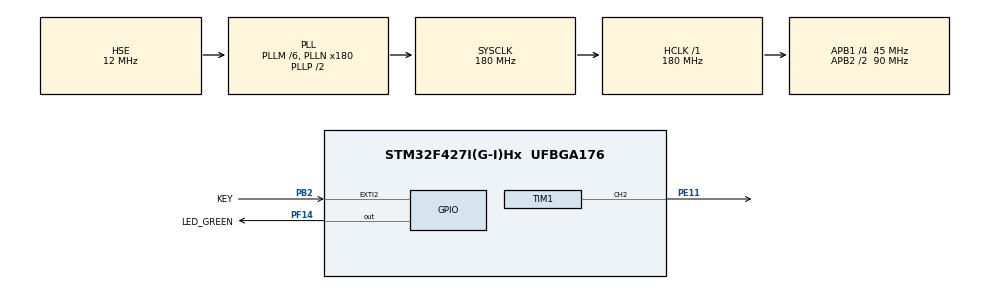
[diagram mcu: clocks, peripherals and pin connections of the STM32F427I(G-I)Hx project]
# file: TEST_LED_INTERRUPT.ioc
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Mcu.Family=STM32F4
Mcu.Name=STM32F427I(G-I)Hx
Mcu.Package=UFBGA176
NVIC.EXTI2_IRQn=true\:0\:0\:false\:false\:true\:true\:true\:true
NVIC.PriorityGroup=NVIC_PRIORITYGROUP_4
NVIC.TIM1_UP_TIM10_IRQn=true\:0\:0\:false\:false\:true\:true\:true\:true
NVIC.TIM6_DAC_IRQn=true\:0\:0\:false\:false\:true\:true\:true\:true
PA13.Mode=Serial_Wire
PA13.Signal=SYS_JTMS-SWDIO
PA14.Mode=Serial_Wire
PA14.Signal=SYS_JTCK-SWCLK
PB2/BOOT1.GPIO_Label=KEY
PB2/BOOT1.Signal=GPXTI2
PE11.Signal=S_TIM1_CH2
PF14.GPIO_Label=LED_GREEN
PF14.Signal=GPIO_Output
PH0/OSC_IN.Mode=HSE-External-Oscillator
PH0/OSC_IN.Signal=RCC_OSC_IN
PH1/OSC_OUT.Mode=HSE-External-Oscillator
PH1/OSC_OUT.Signal=RCC_OSC_OUT
ProjectManager.HeapSize=0x200
ProjectManager.StackSize=0x400
ProjectManager.TargetToolchain=MDK-ARM V5.32
RCC.48MHZClocksFreq_Value=90000000
RCC.AHBFreq_Value=180000000
RCC.APB1CLKDivider=RCC_HCLK_DIV4
RCC.APB1Freq_Value=45000000
RCC.APB1TimFreq_Value=90000000
RCC.APB2CLKDivider=RCC_HCLK_DIV2
RCC.APB2Freq_Value=90000000
RCC.APB2TimFreq_Value=180000000
RCC.CortexFreq_Value=180000000
RCC.HCLKFreq_Value=180000000
RCC.HSE_VALUE=12000000
RCC.HSI_VALUE=16000000
RCC.LSE_VALUE=32768
RCC.PLLM=6
RCC.PLLN=180
RCC.PLLSourceVirtual=RCC_PLLSOURCE_HSE
RCC.SYSCLKFreq_VALUE=180000000
RCC.SYSCLKSource=RCC_SYSCLKSOURCE_PLLCLK
RCC.VCOOutputFreq_Value=360000000
SH.S_TIM1_CH2.0=TIM1_CH2,PWM Generation2 CH2
TIM1.Channel-PWM\ Generation2\ CH2=TIM_CHANNEL_2
TIM1.Period=2999
TIM1.Prescaler=59999
TIM1.Pulse-PWM\ Generation2\ CH2=1500
TIM6.Period=99
TIM6.Prescaler=59999
VP_TIM1_VS_ClockSourceINT.Mode=Internal
VP_TIM6_VS_ClockSourceINT.Mode=Enable_Timer
board=custom

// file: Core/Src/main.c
/* USER CODE BEGIN Header */
/**
  ******************************************************************************
  * @file           : main.c
  * @brief          : Main program body
  ******************************************************************************
  * @attention
  *
  * Copyright (c) 2024 STMicroelectronics.
  * All rights reserved.
  *
  * This software is licensed under terms that can be found in the LICENSE file
  * in the root directory of this software component.
  * If no LICENSE file comes with this software, it is provided AS-IS.
  *
  ******************************************************************************
  */
/* USER CODE END Header */
#include "main.h"
#include "tim.h"
#include "gpio.h"

void SystemClock_Config(void);

int main(void)
{

  /* MCU Configuration--------------------------------------------------------*/

  /* Reset of all peripherals, Initializes the Flash interface and the Systick. */
  HAL_Init();

  /* Configure the system clock */
  SystemClock_Config();

  /* Initialize all configured peripherals */
  MX_GPIO_Init();
  MX_TIM1_Init();
  MX_TIM6_Init();
  /* USER CODE BEGIN 2 */
  HAL_TIM_Base_Start_IT(&htim1);
  HAL_TIM_Base_Start_IT(&htim6);
  HAL_TIM_PWM_Start(&htim1, TIM_CHANNEL_2);

  /* USER CODE END 2 */

  /* Infinite loop */
  while (1)
  {

    /* USER CODE BEGIN 3 */
		//HAL_Delay(1000);
    //HAL_GPIO_TogglePin(LED_GREEN_GPIO_Port, LED_GREEN_Pin);
  }
  /* USER CODE END 3 */
}

void SystemClock_Config(void)
{
  RCC_OscInitTypeDef RCC_OscInitStruct = {0};
  RCC_ClkInitTypeDef RCC_ClkInitStruct = {0};

  /** Configure the main internal regulator output voltage
  */
  __HAL_RCC_PWR_CLK_ENABLE();
  __HAL_PWR_VOLTAGESCALING_CONFIG(PWR_REGULATOR_VOLTAGE_SCALE1);

  /** Initializes the RCC Oscillators according to the specified parameters
  * in the RCC_OscInitTypeDef structure.
  */
  RCC_OscInitStruct.OscillatorType = RCC_OSCILLATORTYPE_HSE;
  RCC_OscInitStruct.HSEState = RCC_HSE_ON;
  RCC_OscInitStruct.PLL.PLLState = RCC_PLL_ON;
  RCC_OscInitStruct.PLL.PLLSource = RCC_PLLSOURCE_HSE;
  RCC_OscInitStruct.PLL.PLLM = 6;
  RCC_OscInitStruct.PLL.PLLN = 180;
  RCC_OscInitStruct.PLL.PLLP = RCC_PLLP_DIV2;
  RCC_OscInitStruct.PLL.PLLQ = 4;
  if (HAL_RCC_OscConfig(&RCC_OscInitStruct) != HAL_OK)
  {
    Error_Handler();
  }

  /** Activate the Over-Drive mode
  */
  if (HAL_PWREx_EnableOverDrive() != HAL_OK)
  {
    Error_Handler();
  }

  /** Initializes the CPU, AHB and APB buses clocks
  */
  RCC_ClkInitStruct.ClockType = RCC_CLOCKTYPE_HCLK|RCC_CLOCKTYPE_SYSCLK
                              |RCC_CLOCKTYPE_PCLK1|RCC_CLOCKTYPE_PCLK2;
  RCC_ClkInitStruct.SYSCLKSource = RCC_SYSCLKSOURCE_PLLCLK;
  RCC_ClkInitStruct.AHBCLKDivider = RCC_SYSCLK_DIV1;
  RCC_ClkInitStruct.APB1CLKDivider = RCC_HCLK_DIV4;
  RCC_ClkInitStruct.APB2CLKDivider = RCC_HCLK_DIV2;

  if (HAL_RCC_ClockConfig(&RCC_ClkInitStruct, FLASH_LATENCY_5) != HAL_OK)
  {
    Error_Handler();
  }
}

/* USER CODE BEGIN 4 */
void Nothing() {
  HAL_Delay(50);
}
void Happyhappyhappy() {
  Nothing();
}
/* USER CODE END 4 */

void Error_Handler(void)
{
  __disable_irq();
  while (1)
  {
  }
}
